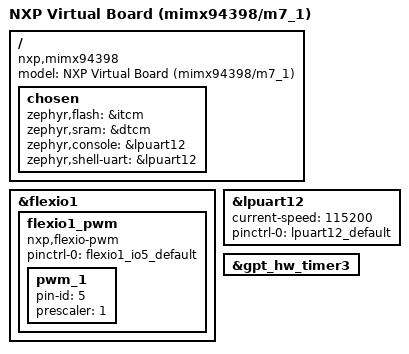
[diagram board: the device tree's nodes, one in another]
/* Auto-generated by gen_nxp_virtual_board.py */
/* Master DTS template: boards/nxp/imx943_evk/imx943_evk_mimx94398_m7_1.dts */
/*
 * Copyright 2025 NXP
 *
 * SPDX-License-Identifier: Apache-2.0
 */

/dts-v1/;

#include <nxp/nxp_imx943_m7_1.dtsi>
#include "imx943_evk-pinctrl.dtsi"

/ {
	model = "NXP Virtual Board (mimx94398/m7_1)";
	compatible = "nxp,mimx94398";

	chosen {
		zephyr,flash = &itcm;
		zephyr,sram = &dtcm;

		zephyr,console = &lpuart12;
		zephyr,shell-uart = &lpuart12;
	};
};

&flexio1 {
	status = "okay";

	/* Signal can be checked by the connector J44 Pin10(M1_LED_TP1) via logic analyzer */
	flexio1_pwm: flexio1_pwm {
		compatible = "nxp,flexio-pwm";
		#pwm-cells = <3>;
		pinctrl-0 = <&flexio1_io5_default>;
		pinctrl-names = "default";

		pwm_1 {
			pin-id = <5>;
			prescaler = <1>;
		};

		status = "okay";
	};
};

&lpuart12 {
	status = "okay";
	current-speed = <115200>;
	pinctrl-0 = <&lpuart12_default>;
	pinctrl-names = "default";
};

&gpt_hw_timer3 {
	status = "okay";
};
